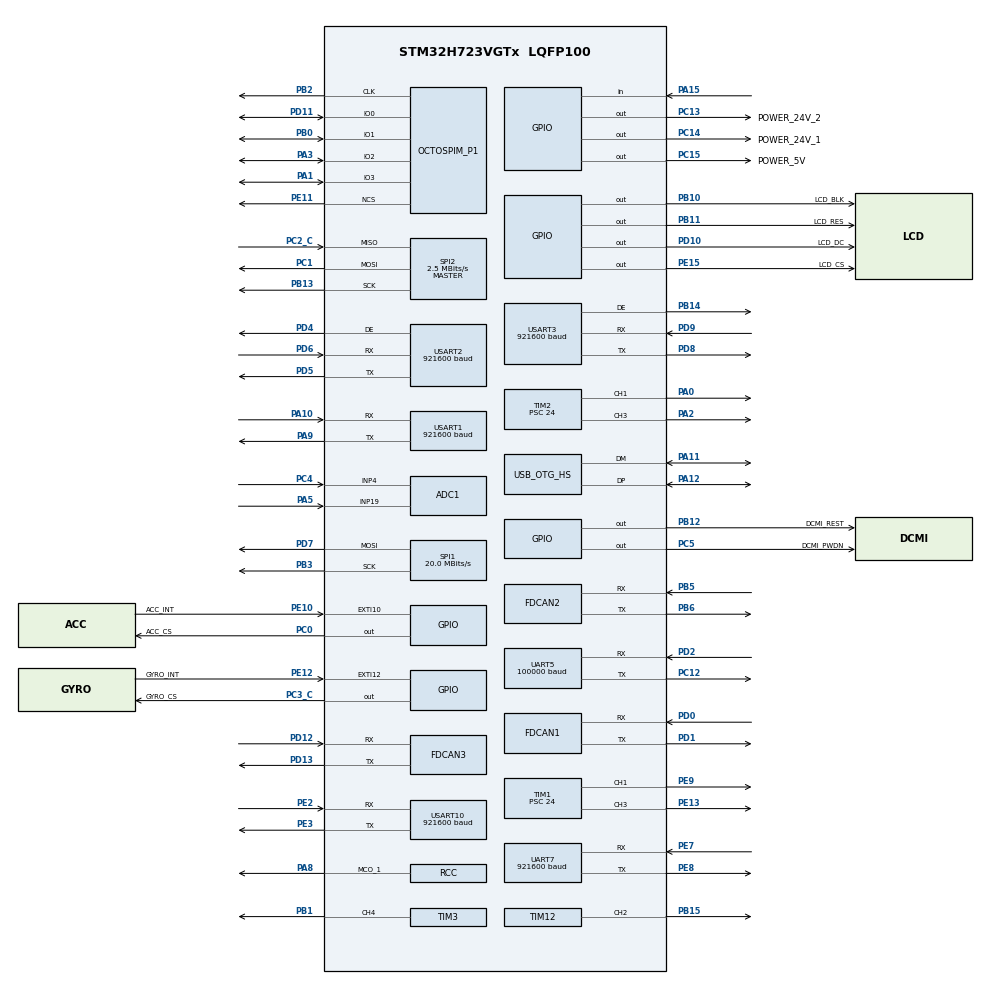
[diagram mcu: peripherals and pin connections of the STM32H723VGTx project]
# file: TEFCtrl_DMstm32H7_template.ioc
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ADC1.Channel-0\#ChannelRegularConversion=ADC_CHANNEL_4
ADC1.Channel-1\#ChannelRegularConversion=ADC_CHANNEL_19
ADC1.ClockPrescaler=ADC_CLOCK_ASYNC_DIV64
ADC1.ContinuousConvMode=ENABLE
ADC1.ConversionDataManagement=ADC_CONVERSIONDATA_DMA_CIRCULAR
ADC1.NbrOfConversion=2
ADC1.NbrOfConversionFlag=1
ADC1.OffsetNumber-0\#ChannelRegularConversion=ADC_OFFSET_NONE
ADC1.OffsetNumber-1\#ChannelRegularConversion=ADC_OFFSET_NONE
ADC1.OffsetSignedSaturation-0\#ChannelRegularConversion=DISABLE
ADC1.OffsetSignedSaturation-1\#ChannelRegularConversion=DISABLE
ADC1.Rank-0\#ChannelRegularConversion=1
ADC1.Rank-1\#ChannelRegularConversion=2
ADC1.SamplingTime-0\#ChannelRegularConversion=ADC_SAMPLETIME_32CYCLES_5
ADC1.SamplingTime-1\#ChannelRegularConversion=ADC_SAMPLETIME_32CYCLES_5
ADC1.master=1
ADC3.Channel-1\#ChannelRegularConversion=ADC_CHANNEL_TEMPSENSOR
ADC3.NbrOfConversionFlag=1
ADC3.OffsetNumber-1\#ChannelRegularConversion=ADC_OFFSET_NONE
ADC3.OffsetSign-1\#ChannelRegularConversion=ADC3_OFFSET_SIGN_NEGATIVE
ADC3.Rank-1\#ChannelRegularConversion=1
ADC3.SamplingTime-1\#ChannelRegularConversion=ADC3_SAMPLETIME_640CYCLES_5
CORTEX_M7.BaseAddress-Cortex_Memory_Protection_Unit_Region0_Settings=0x24000000
CORTEX_M7.CPU_DCache=Disabled
CORTEX_M7.CPU_ICache=Disabled
CORTEX_M7.Enable-Cortex_Memory_Protection_Unit_Region0_Settings=MPU_REGION_ENABLE
CORTEX_M7.IsBufferable-Cortex_Memory_Protection_Unit_Region0_Settings=MPU_ACCESS_BUFFERABLE
CORTEX_M7.IsCacheable-Cortex_Memory_Protection_Unit_Region0_Settings=MPU_ACCESS_CACHEABLE
CORTEX_M7.MPU_Control=__NULL
CORTEX_M7.Size-Cortex_Memory_Protection_Unit_Region0_Settings=MPU_REGION_SIZE_512B
CORTEX_M7.TypeExtField-Cortex_Memory_Protection_Unit_Region0_Settings=MPU_TEX_LEVEL1
Dma.ADC1.0.Direction=DMA_PERIPH_TO_MEMORY
Dma.ADC1.0.EventEnable=DISABLE
Dma.ADC1.0.FIFOMode=DMA_FIFOMODE_DISABLE
Dma.ADC1.0.Instance=DMA1_Stream0
Dma.ADC1.0.MemDataAlignment=DMA_MDATAALIGN_HALFWORD
Dma.ADC1.0.MemInc=DMA_MINC_ENABLE
Dma.ADC1.0.Mode=DMA_CIRCULAR
Dma.ADC1.0.PeriphDataAlignment=DMA_PDATAALIGN_HALFWORD
Dma.ADC1.0.PeriphInc=DMA_PINC_DISABLE
Dma.ADC1.0.Polarity=HAL_DMAMUX_REQ_GEN_RISING
Dma.ADC1.0.Priority=DMA_PRIORITY_LOW
Dma.ADC1.0.RequestNumber=1
Dma.ADC1.0.SignalID=NONE
Dma.ADC1.0.SyncEnable=DISABLE
Dma.ADC1.0.SyncPolarity=HAL_DMAMUX_SYNC_NO_EVENT
Dma.ADC1.0.SyncRequestNumber=1
Dma.ADC1.0.SyncSignalID=NONE
Dma.Request0=ADC1
Dma.Request1=UART5_RX
Dma.UART5_RX.1.Direction=DMA_PERIPH_TO_MEMORY
Dma.UART5_RX.1.EventEnable=DISABLE
Dma.UART5_RX.1.FIFOMode=DMA_FIFOMODE_DISABLE
Dma.UART5_RX.1.Instance=DMA1_Stream1
Dma.UART5_RX.1.MemDataAlignment=DMA_MDATAALIGN_BYTE
Dma.UART5_RX.1.MemInc=DMA_MINC_ENABLE
Dma.UART5_RX.1.Mode=DMA_NORMAL
Dma.UART5_RX.1.PeriphDataAlignment=DMA_PDATAALIGN_BYTE
Dma.UART5_RX.1.PeriphInc=DMA_PINC_DISABLE
Dma.UART5_RX.1.Polarity=HAL_DMAMUX_REQ_GEN_RISING
Dma.UART5_RX.1.Priority=DMA_PRIORITY_HIGH
Dma.UART5_RX.1.RequestNumber=1
Dma.UART5_RX.1.SignalID=NONE
Dma.UART5_RX.1.SyncEnable=DISABLE
Dma.UART5_RX.1.SyncPolarity=HAL_DMAMUX_SYNC_NO_EVENT
Dma.UART5_RX.1.SyncRequestNumber=1
Dma.UART5_RX.1.SyncSignalID=NONE
FDCAN1.AutoRetransmission=ENABLE
FDCAN1.CalculateBaudRateNominal=1000000
FDCAN1.CalculateTimeBitNominal=1000
FDCAN1.CalculateTimeQuantumNominal=12.5
FDCAN1.DataSyncJumpWidth=2
FDCAN1.DataTimeSeg1=13
FDCAN1.DataTimeSeg2=2
FDCAN1.ExtFiltersNbr=4
FDCAN1.FrameFormat=FDCAN_FRAME_FD_BRS
FDCAN1.NominalPrescaler=1
FDCAN1.NominalSyncJumpWidth=20
FDCAN1.NominalTimeSeg1=59
FDCAN1.NominalTimeSeg2=20
FDCAN1.ProtocolException=ENABLE
FDCAN1.RxBuffersNbr=2
FDCAN1.RxFifo0ElmtsNbr=10
FDCAN1.RxFifo1ElmtsNbr=10
FDCAN1.StdFiltersNbr=4
FDCAN1.TxBuffersNbr=10
FDCAN1.TxEventsNbr=10
FDCAN1.TxFifoQueueElmtsNbr=10
FDCAN2.CalculateBaudRateNominal=1666666
FDCAN2.CalculateTimeBitNominal=600
FDCAN2.CalculateTimeQuantumNominal=200.0
FDCAN3.CalculateBaudRateNominal=1111111
FDCAN3.CalculateTimeBitNominal=900
FDCAN3.CalculateTimeQuantumNominal=300.0
FDCAN3.MessageRAMOffset=0x812
FDCAN3.NominalPrescaler=24
FDCAN3.RxFifo0ElmtsNbr=32
FDCAN3.StdFiltersNbr=1
FDCAN3.TxFifoQueueElmtsNbr=32
Mcu.Family=STM32H7
Mcu.Name=STM32H723VGTx
Mcu.Package=LQFP100
NVIC.DMA1_Stream0_IRQn=true\:0\:0\:false\:false\:true\:false\:true\:true
NVIC.DMA1_Stream1_IRQn=true\:0\:0\:false\:false\:true\:false\:true\:true
NVIC.FDCAN1_IT0_IRQn=true\:0\:0\:false\:false\:true\:true\:true\:true
NVIC.FDCAN1_IT1_IRQn=true\:0\:0\:false\:false\:true\:true\:true\:true
NVIC.FDCAN3_IT0_IRQn=true\:0\:0\:false\:false\:true\:true\:true\:true
NVIC.FDCAN3_IT1_IRQn=true\:0\:0\:false\:false\:true\:true\:true\:true
NVIC.FDCAN_CAL_IRQn=true\:0\:0\:false\:false\:true\:true\:true\:true
NVIC.OTG_HS_IRQn=true\:0\:0\:false\:false\:true\:false\:true\:true
NVIC.PriorityGroup=NVIC_PRIORITYGROUP_4
NVIC.UART5_IRQn=true\:0\:0\:false\:false\:true\:true\:true\:true
NVIC.UART7_IRQn=true\:5\:0\:true\:false\:true\:true\:true\:true
NVIC.USART10_IRQn=true\:5\:0\:true\:false\:true\:true\:true\:true
NVIC.USART1_IRQn=true\:5\:0\:true\:false\:true\:true\:true\:true
NVIC.USART2_IRQn=true\:5\:0\:true\:false\:true\:true\:true\:true
NVIC.USART3_IRQn=true\:5\:0\:true\:false\:true\:true\:true\:true
OCTOSPI2.ClockMode=HAL_OSPI_CLOCK_MODE_3
OCTOSPI2.ClockPrescaler=3
OCTOSPI2.DeviceSize=23
OCTOSPI2.DeviceType=SPI_DEVICE_FLASH
OCTOSPI2.FifoThreshold=8
OCTOSPI2.SampleShifting=HAL_OSPI_SAMPLE_SHIFTING_HALFCYCLE
PA0.Signal=S_TIM2_CH1_ETR
PA1.Mode=OCTOSPI2_IOL_Port1L
PA1.Signal=OCTOSPIM_P1_IO3
PA10.Mode=Asynchronous
PA10.Signal=USART1_RX
PA11.Mode=Device_Only_FS
PA11.Signal=USB_OTG_HS_DM
PA12.Mode=Device_Only_FS
PA12.Signal=USB_OTG_HS_DP
PA13(JTMS/SWDIO).Mode=Serial_Wire
PA13(JTMS/SWDIO).Signal=DEBUG_JTMS-SWDIO
PA14(JTCK/SWCLK).Mode=Serial_Wire
PA14(JTCK/SWCLK).Signal=DEBUG_JTCK-SWCLK
PA15(JTDI).Signal=GPIO_Input
PA2.Signal=S_TIM2_CH3
PA3.Mode=OCTOSPI2_IOL_Port1L
PA3.Signal=OCTOSPIM_P1_IO2
PA5.Signal=ADCx_INP19
PA8.Mode=Clock-out-1
PA8.Signal=RCC_MCO_1
PA9.Mode=Asynchronous
PA9.Signal=USART1_TX
PB0.Mode=OCTOSPI2_IOL_Port1L
PB0.Signal=OCTOSPIM_P1_IO1
PB1.Signal=S_TIM3_CH4
PB10.GPIO_Label=LCD_BLK
PB10.Signal=GPIO_Output
PB11.GPIO_Label=LCD_RES
PB11.Signal=GPIO_Output
PB12.GPIO_Label=DCMI_REST
PB12.GPIO_PuPd=GPIO_PULLUP
PB12.GPIO_Speed=GPIO_SPEED_FREQ_VERY_HIGH
PB12.PinState=GPIO_PIN_SET
PB12.Signal=GPIO_Output
PB13.GPIO_Speed=GPIO_SPEED_FREQ_VERY_HIGH
PB13.Mode=Full_Duplex_Master
PB13.Signal=SPI2_SCK
PB14.Mode=Hardware Flow Control (RS485)
PB14.Signal=USART3_DE
PB15.Signal=S_TIM12_CH2
PB2.Mode=O2_P1_CLK
PB2.Signal=OCTOSPIM_P1_CLK
PB3(JTDO/TRACESWO).GPIO_Speed=GPIO_SPEED_FREQ_VERY_HIGH
PB3(JTDO/TRACESWO).Mode=TX_Only_Simplex_Unidirect_Master
PB3(JTDO/TRACESWO).Signal=SPI1_SCK
PB5.Mode=FDCAN_Activate
PB5.Signal=FDCAN2_RX
PB6.Mode=FDCAN_Activate
PB6.Signal=FDCAN2_TX
PC0.GPIO_Label=ACC_CS
PC0.GPIO_Speed=GPIO_SPEED_FREQ_VERY_HIGH
PC0.PinState=GPIO_PIN_SET
PC0.Signal=GPIO_Output
PC1.GPIO_Speed=GPIO_SPEED_FREQ_VERY_HIGH
PC1.Mode=Full_Duplex_Master
PC1.Signal=SPI2_MOSI
PC12.Mode=Asynchronous
PC12.Signal=UART5_TX
PC13.GPIO_Label=POWER_24V_2
PC13.PinState=GPIO_PIN_SET
PC13.Signal=GPIO_Output
PC14-OSC32_IN.GPIO_Label=POWER_24V_1
PC14-OSC32_IN.PinState=GPIO_PIN_SET
PC14-OSC32_IN.Signal=GPIO_Output
PC15-OSC32_OUT.GPIO_Label=POWER_5V
PC15-OSC32_OUT.PinState=GPIO_PIN_SET
PC15-OSC32_OUT.Signal=GPIO_Output
PC2_C.GPIO_Speed=GPIO_SPEED_FREQ_VERY_HIGH
PC2_C.Mode=Full_Duplex_Master
PC2_C.Signal=SPI2_MISO
PC3_C.GPIO_Label=GYRO_CS
PC3_C.GPIO_Speed=GPIO_SPEED_FREQ_VERY_HIGH
PC3_C.PinState=GPIO_PIN_SET
PC3_C.Signal=GPIO_Output
PC4.Signal=ADCx_INP4
PC5.GPIO_Label=DCMI_PWDN
PC5.GPIO_PuPd=GPIO_NOPULL
PC5.GPIO_Speed=GPIO_SPEED_FREQ_VERY_HIGH
PC5.PinState=GPIO_PIN_SET
PC5.Signal=GPIO_Output
PD0.Mode=FDCAN_Activate
PD0.Signal=FDCAN1_RX
PD1.Mode=FDCAN_Activate
PD1.Signal=FDCAN1_TX
PD10.GPIO_Label=LCD_DC
PD10.Signal=GPIO_Output
PD11.Mode=OCTOSPI2_IOL_Port1L
PD11.Signal=OCTOSPIM_P1_IO0
PD12.Mode=FDCAN_Activate
PD12.Signal=FDCAN3_RX
PD13.Mode=FDCAN_Activate
PD13.Signal=FDCAN3_TX
PD2.Mode=Asynchronous
PD2.Signal=UART5_RX
PD4.Mode=Hardware Flow Control (RS485)
PD4.Signal=USART2_DE
PD5.Mode=Asynchronous
PD5.Signal=USART2_TX
PD6.Mode=Asynchronous
PD6.Signal=USART2_RX
PD7.GPIO_Speed=GPIO_SPEED_FREQ_VERY_HIGH
PD7.Mode=TX_Only_Simplex_Unidirect_Master
PD7.Signal=SPI1_MOSI
PD8.Mode=Asynchronous
PD8.Signal=USART3_TX
PD9.Mode=Asynchronous
PD9.Signal=USART3_RX
PE10.GPIO_Label=ACC_INT
PE10.Signal=GPXTI10
PE11.Mode=OCTOSPI2_Port1_NCS
PE11.Signal=OCTOSPIM_P1_NCS
PE12.GPIO_Label=GYRO_INT
PE12.Signal=GPXTI12
PE13.Signal=S_TIM1_CH3
PE15.GPIO_Label=LCD_CS
PE15.Signal=GPIO_Output
PE2.Mode=Asynchronous
PE2.Signal=USART10_RX
PE3.Mode=Asynchronous
PE3.Signal=USART10_TX
PE7.Mode=Asynchronous
PE7.Signal=UART7_RX
PE8.Mode=Asynchronous
PE8.Signal=UART7_TX
PE9.Signal=S_TIM1_CH1
PH0-OSC_IN.Mode=HSE-External-Oscillator
PH0-OSC_IN.Signal=RCC_OSC_IN
PH1-OSC_OUT.Mode=HSE-External-Oscillator
PH1-OSC_OUT.Signal=RCC_OSC_OUT
ProjectManager.HeapSize=0x200
ProjectManager.StackSize=0x800
ProjectManager.TargetToolchain=STM32CubeIDE
RCC.ADCFreq_Value=96000000
RCC.APB1Freq_Value=120000000
RCC.APB2Freq_Value=120000000
RCC.APB3Freq_Value=120000000
RCC.APB4Freq_Value=120000000
RCC.CortexFreq_Value=480000000
RCC.D1PPRE=RCC_APB3_DIV2
RCC.D2PPRE1=RCC_APB1_DIV2
RCC.D2PPRE2=RCC_APB2_DIV2
RCC.D3PPRE=RCC_APB4_DIV2
RCC.DIVM1=2
RCC.DIVM2=2
RCC.DIVN1=40
RCC.DIVN2=16
RCC.DIVP1=1
RCC.DIVQ1=6
RCC.EnbaleCSS=false
RCC.HCLKFreq_Value=240000000
RCC.HPRE=RCC_HCLK_DIV2
RCC.HSE_VALUE=24000000
RCC.PLL2FRACN=0
RCC.PLL2_VCI_Range-AdvancedSettings=RCC_PLL2VCIRANGE_0
RCC.PLL2_VCO_SEL-AdvancedSettings=RCC_PLL2VCOWIDE
RCC.PLL3FRACN=0
RCC.PLL3_VCO_SEL-AdvancedSettings=RCC_PLL3VCOMEDIUM
RCC.PLLFRACN=0
RCC.PLLSourceVirtual=RCC_PLLSOURCE_HSE
RCC.SPI6CLockSelection=RCC_SPI6CLKSOURCE_HSE
RCC.SYSCLKFreq_VALUE=480000000
RCC.SYSCLKSource=RCC_SYSCLKSOURCE_PLLCLK
RCC.USBCLockSelection=RCC_USBCLKSOURCE_HSI48
RCC.USBFreq_Value=48000000
SH.ADCx_INP19.0=ADC1_INP19,IN19-Single-Ended
SH.ADCx_INP4.0=ADC1_INP4,IN4-Single-Ended
SH.S_TIM12_CH2.0=TIM12_CH2,PWM Generation2 CH2
SH.S_TIM1_CH1.0=TIM1_CH1,PWM Generation1 CH1
SH.S_TIM1_CH3.0=TIM1_CH3,PWM Generation3 CH3
SH.S_TIM2_CH1_ETR.0=TIM2_CH1,PWM Generation1 CH1
SH.S_TIM2_CH3.0=TIM2_CH3,PWM Generation3 CH3
SH.S_TIM3_CH4.0=TIM3_CH4,PWM Generation4 CH4
SPI1.BaudRatePrescaler=SPI_BAUDRATEPRESCALER_4
SPI1.CLKPolarity=SPI_POLARITY_HIGH
SPI1.CalculateBaudRate=20.0 MBits/s
SPI1.DataSize=SPI_DATASIZE_8BIT
SPI1.Direction=SPI_DIRECTION_2LINES_TXONLY
SPI1.Mode=SPI_MODE_MASTER
SPI1.VirtualType=VM_MASTER
SPI2.BaudRatePrescaler=SPI_BAUDRATEPRESCALER_32
SPI2.CLKPhase=SPI_PHASE_2EDGE
SPI2.CLKPolarity=SPI_POLARITY_HIGH
SPI2.CalculateBaudRate=2.5 MBits/s
SPI2.DataSize=SPI_DATASIZE_8BIT
SPI2.Direction=SPI_DIRECTION_2LINES
SPI2.Mode=SPI_MODE_MASTER
SPI2.VirtualType=VM_MASTER
STMicroelectronics.X-CUBE-ALGOBUILD.1.4.0.LibraryCcDSPOoLibraryJjDSPOoLibrary=true
TIM1.Channel-PWM\ Generation1\ CH1=TIM_CHANNEL_1
TIM1.Channel-PWM\ Generation3\ CH3=TIM_CHANNEL_3
TIM1.Period=10000
TIM1.Prescaler=24
TIM1.Pulse-PWM\ Generation1\ CH1=5000
TIM1.Pulse-PWM\ Generation3\ CH3=5000
TIM12.Channel-PWM\ Generation2\ CH2=TIM_CHANNEL_2
TIM12.Period=2000-1
TIM12.Prescaler=24-1
TIM2.Channel-PWM\ Generation1\ CH1=TIM_CHANNEL_1
TIM2.Channel-PWM\ Generation3\ CH3=TIM_CHANNEL_3
TIM2.Period=10000
TIM2.Prescaler=24
TIM2.Pulse-PWM\ Generation1\ CH1=5000
TIM2.Pulse-PWM\ Generation3\ CH3=5000
TIM3.AutoReloadPreload=TIM_AUTORELOAD_PRELOAD_ENABLE
TIM3.Channel-PWM\ Generation4\ CH4=TIM_CHANNEL_4
TIM3.Period=10000-1
TIM3.Prescaler=24-1
UART5.BaudRate=100000
UART5.Mode=MODE_RX
UART5.Parity=PARITY_EVEN
UART5.StopBits=UART_STOPBITS_1
UART5.WordLength=WORDLENGTH_9B
UART7.BaudRate=921600
USART1.BaudRate=921600
USART1.VirtualMode-Asynchronous=VM_ASYNC
USART10.BaudRate=921600
USART10.VirtualMode=VM_ASYNC
USART2.BaudRate=921600
USART2.VirtualMode-Asynchronous=VM_ASYNC
USART2.VirtualMode-Hardware\ Flow\ Control\ (RS485)=VM_ASYNC
USART3.BaudRate=921600
USART3.VirtualMode-Asynchronous=VM_ASYNC
USART3.VirtualMode-Hardware\ Flow\ Control\ (RS485)=VM_ASYNC
USB_DEVICE.CLASS_NAME_HS=CDC
USB_DEVICE.VirtualMode=Cdc
USB_DEVICE.VirtualModeHS=Cdc_HS
USB_OTG_HS.VirtualMode-Device_Only_FS=Device_Only_FS
VP_ADC3_TempSens_Input.Mode=IN-TempSens
VP_MEMORYMAP_VS_MEMORYMAP.Mode=CurAppReg
VP_OCTOSPI2_VS_quad.Mode=quad_mode
VP_STMicroelectronics.X-CUBE-ALGOBUILD_VS_DSPOoLibraryJjLibrary_1.4.0_1.4.0.Mode=DSPOoLibraryJjLibrary
VP_USB_DEVICE_VS_USB_DEVICE_CDC_HS.Mode=CDC_HS
board=custom

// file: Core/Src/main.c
/* USER CODE BEGIN Header */
/**
  ******************************************************************************
  * @file           : main.c
  * @brief          : Main program body
  ******************************************************************************
  * @attention
  *
  * Copyright (c) 2026 STMicroelectronics.
  * All rights reserved.
  *
  * This software is licensed under terms that can be found in the LICENSE file
  * in the root directory of this software component.
  * If no LICENSE file comes with this software, it is provided AS-IS.
  *
  ******************************************************************************
  */
/* USER CODE END Header */
#include "main.h"
#include "adc.h"
#include "dma.h"
#include "fdcan.h"
#include "memorymap.h"
#include "octospi.h"
#include "spi.h"
#include "tim.h"
#include "usart.h"
#include "usb_device.h"
#include "gpio.h"

/* USER CODE BEGIN Includes */
#include "app_main.h"
/* USER CODE END Includes */

void SystemClock_Config(void);
void PeriphCommonClock_Config(void);

/**
 * @note  RT-Thread GCC 启动流程：
 *        startup.s → entry() → rtthread_startup() → rt_hw_board_init()
 *                 （board.c 完成 HAL_Init + SystemClock_Config + SysTick）
 *        → 创建 main 线程 → 调度器启动 → main 线程调用 main()
 *        main() 此时在 RT-Thread 线程上下文中执行，可直接初始化外设和创建线程。
 */
int main(void)
{

  /* MCU Configuration -------------------------------------------------------
   * 注意：HAL_Init / SystemClock_Config / PeriphCommonClock_Config
   * 已在 board.c 的 rt_hw_board_init() 中完成，此处无需重复调用。
   * -------------------------------------------------------------------------*/

  /* Initialize all configured peripherals */
  MX_GPIO_Init();
  MX_DMA_Init();
  MX_ADC1_Init();
  MX_USB_DEVICE_Init();
  MX_TIM12_Init();
  MX_SPI1_Init();
  MX_SPI2_Init();
  MX_TIM3_Init();
  MX_USART1_UART_Init();
  MX_USART2_UART_Init();
  MX_USART3_UART_Init();
  MX_UART7_Init();
  MX_USART10_UART_Init();
  MX_FDCAN1_Init();
  MX_FDCAN2_Init();
  MX_FDCAN3_Init();
  MX_TIM1_Init();
  MX_TIM2_Init();
  MX_OCTOSPI2_Init();
  MX_ADC3_Init();
  MX_UART5_Init();

  /* USER CODE BEGIN 2 */
  app_main_init();        /* BSP 应用层初始化（CAN/UART/Remote 等） */
  rtt_app_threads_init(); /* 创建业务线程（当前已在 RT-Thread main 线程中） */
  /* USER CODE END 2 */

  /* main 线程正常退出，RT-Thread 调度器继续运行其他线程 */
  return 0;
}

void SystemClock_Config(void)
{
  RCC_OscInitTypeDef RCC_OscInitStruct = {0};
  RCC_ClkInitTypeDef RCC_ClkInitStruct = {0};

  /** Supply configuration update enable
  */
  HAL_PWREx_ConfigSupply(PWR_LDO_SUPPLY);

  /** Configure the main internal regulator output voltage
  */
  __HAL_PWR_VOLTAGESCALING_CONFIG(PWR_REGULATOR_VOLTAGE_SCALE0);

  while(!__HAL_PWR_GET_FLAG(PWR_FLAG_VOSRDY)) {}

  /** Initializes the RCC Oscillators according to the specified parameters
  * in the RCC_OscInitTypeDef structure.
  */
  RCC_OscInitStruct.OscillatorType = RCC_OSCILLATORTYPE_HSI48|RCC_OSCILLATORTYPE_HSI
                              |RCC_OSCILLATORTYPE_HSE;
  RCC_OscInitStruct.HSEState = RCC_HSE_ON;
  RCC_OscInitStruct.HSIState = RCC_HSI_DIV1;
  RCC_OscInitStruct.HSICalibrationValue = 64;
  RCC_OscInitStruct.HSI48State = RCC_HSI48_ON;
  RCC_OscInitStruct.PLL.PLLState = RCC_PLL_ON;
  RCC_OscInitStruct.PLL.PLLSource = RCC_PLLSOURCE_HSE;
  RCC_OscInitStruct.PLL.PLLM = 2;
  RCC_OscInitStruct.PLL.PLLN = 40;
  RCC_OscInitStruct.PLL.PLLP = 1;
  RCC_OscInitStruct.PLL.PLLQ = 6;
  RCC_OscInitStruct.PLL.PLLR = 2;
  RCC_OscInitStruct.PLL.PLLRGE = RCC_PLL1VCIRANGE_3;
  RCC_OscInitStruct.PLL.PLLVCOSEL = RCC_PLL1VCOWIDE;
  RCC_OscInitStruct.PLL.PLLFRACN = 0;
  if (HAL_RCC_OscConfig(&RCC_OscInitStruct) != HAL_OK)
  {
    Error_Handler();
  }

  /** Initializes the CPU, AHB and APB buses clocks
  */
  RCC_ClkInitStruct.ClockType = RCC_CLOCKTYPE_HCLK|RCC_CLOCKTYPE_SYSCLK
                              |RCC_CLOCKTYPE_PCLK1|RCC_CLOCKTYPE_PCLK2
                              |RCC_CLOCKTYPE_D3PCLK1|RCC_CLOCKTYPE_D1PCLK1;
  RCC_ClkInitStruct.SYSCLKSource = RCC_SYSCLKSOURCE_PLLCLK;
  RCC_ClkInitStruct.SYSCLKDivider = RCC_SYSCLK_DIV1;
  RCC_ClkInitStruct.AHBCLKDivider = RCC_HCLK_DIV2;
  RCC_ClkInitStruct.APB3CLKDivider = RCC_APB3_DIV2;
  RCC_ClkInitStruct.APB1CLKDivider = RCC_APB1_DIV2;
  RCC_ClkInitStruct.APB2CLKDivider = RCC_APB2_DIV2;
  RCC_ClkInitStruct.APB4CLKDivider = RCC_APB4_DIV2;

  if (HAL_RCC_ClockConfig(&RCC_ClkInitStruct, FLASH_LATENCY_3) != HAL_OK)
  {
    Error_Handler();
  }
  HAL_RCC_MCOConfig(RCC_MCO1, RCC_MCO1SOURCE_HSI, RCC_MCODIV_1);
}

void PeriphCommonClock_Config(void)
{
  RCC_PeriphCLKInitTypeDef PeriphClkInitStruct = {0};

  /** Initializes the peripherals clock
  */
  PeriphClkInitStruct.PeriphClockSelection = RCC_PERIPHCLK_ADC;
  PeriphClkInitStruct.PLL2.PLL2M = 2;
  PeriphClkInitStruct.PLL2.PLL2N = 16;
  PeriphClkInitStruct.PLL2.PLL2P = 2;
  PeriphClkInitStruct.PLL2.PLL2Q = 2;
  PeriphClkInitStruct.PLL2.PLL2R = 2;
  PeriphClkInitStruct.PLL2.PLL2RGE = RCC_PLL2VCIRANGE_3;
  PeriphClkInitStruct.PLL2.PLL2VCOSEL = RCC_PLL2VCOWIDE;
  PeriphClkInitStruct.PLL2.PLL2FRACN = 0;
  PeriphClkInitStruct.AdcClockSelection = RCC_ADCCLKSOURCE_PLL2;
  if (HAL_RCCEx_PeriphCLKConfig(&PeriphClkInitStruct) != HAL_OK)
  {
    Error_Handler();
  }
}

void Error_Handler(void)
{
  __disable_irq();
  while (1)
  {
  }
}
